AUTOSAR XML (schema 4-0-3)
package /ComponentTypes
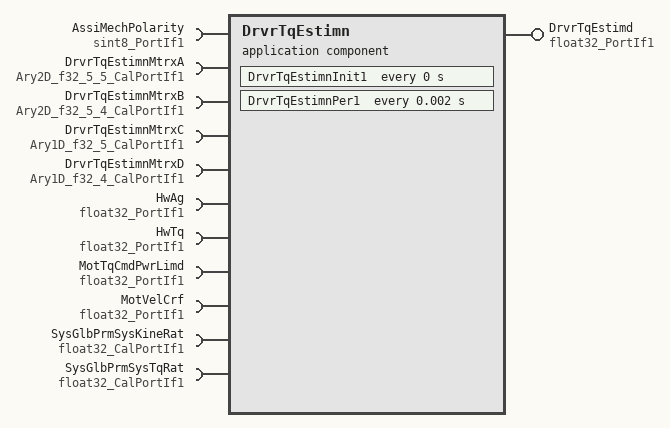
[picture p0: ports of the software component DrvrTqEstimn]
  application sw component type DrvrTqEstimn
    provide port DrvrTqEstimd: nonqueued-sender-com-spec{data-element=Val, init-value=0}, provided-interface=float32_PortIf1
    11 x require port:
      AssiMechPolarity: nonqueued-receiver-com-spec{data-element=Val, filter=data-filter-type=ALWAYS, init-value=1}, required-interface=sint8_PortIf1
      DrvrTqEstimnMtrxA: parameter-require-com-spec{init-value=[[-0.17159, 0.00010352, 1.1696, 0.00024516, 0.000019834], [-240.58, 0.060289, 240.53, 0.17028, 0.047148], [0.0018246, -0.0000042826, 0.99616, 0.00025897, -0.00000028965], [-6.1943, 0.014635, 5.9127, 0.11656, 0.00098854], [-70.875, -0.28572, 70.86, 0.053221, 0.98679]], parameter=Ary2D}, required-interface=Ary2D_f32_5_5_CalPortIf1
      DrvrTqEstimnMtrxB: parameter-require-com-spec{init-value=[[0.00000032994, 0.0081464, 0.0019034, 0.0016485], [0.00045434, 1.6329, 0.0015119, 0.76734], [0.0000011488, -0.000024566, 0.0019002, 0.001743], [0.0027499, 0.045004, 0.00025007, 0.86756], [0.0001448, 0.50816, -0.000025948, 0.23299]], parameter=Ary2D}, required-interface=Ary2D_f32_5_4_CalPortIf1
      DrvrTqEstimnMtrxC: parameter-require-com-spec{init-value=[0, 0, 0, 0, 1], parameter=Ary1D}, required-interface=Ary1D_f32_5_CalPortIf1
      DrvrTqEstimnMtrxD: parameter-require-com-spec{init-value=[0, 0, 0, 0], parameter=Ary1D}, required-interface=Ary1D_f32_4_CalPortIf1
      HwAg: nonqueued-receiver-com-spec{data-element=Val, filter=data-filter-type=ALWAYS, init-value=0}, required-interface=float32_PortIf1
      HwTq: nonqueued-receiver-com-spec{data-element=Val, filter=data-filter-type=ALWAYS, init-value=0}, required-interface=float32_PortIf1
      MotTqCmdPwrLimd: nonqueued-receiver-com-spec{data-element=Val, filter=data-filter-type=ALWAYS, init-value=0}, required-interface=float32_PortIf1
      MotVelCrf: nonqueued-receiver-com-spec{data-element=Val, filter=data-filter-type=ALWAYS, init-value=0}, required-interface=float32_PortIf1
      SysGlbPrmSysKineRat: parameter-require-com-spec{init-value=22, parameter=Val}, required-interface=float32_CalPortIf1
      SysGlbPrmSysTqRat: parameter-require-com-spec{init-value=20, parameter=Val}, required-interface=float32_CalPortIf1
    behavior DrvrTqEstimn_InternalBehavior
      ar-typed-per-instance-memorys:
        data DrvrTqStPrev: sw-calibration-access=READ-ONLY, type=Ary1D_f32_5
      timing event DrvrTqEstimn_InitEvent: start-on-event=DrvrTqEstimnInit1, period=0
      timing event TMT_DrvrTqEstimnPer1: start-on-event=DrvrTqEstimnPer1, period=0.002
      runnable DrvrTqEstimnInit1
      runnable DrvrTqEstimnPer1
        data-receive-point-by-arguments:
          5 x access:
            REC_AssiMechPolarity_Val: accessed-variable=AssiMechPolarity.Val
            REC_HwAg_Val: accessed-variable=HwAg.Val
            REC_HwTq_Val: accessed-variable=HwTq.Val
            REC_MotTqCmdPwrLimd_Val: accessed-variable=MotTqCmdPwrLimd.Val
            REC_MotVelCrf_Val: accessed-variable=MotVelCrf.Val
        data-send-points:
          access SEND_DrvrTqEstimd_Val: accessed-variable=DrvrTqEstimd.Val
  swc implementation DrvrTqEstimn_Implementation: behavior=DrvrTqEstimn_InternalBehavior
    code-descriptors:
      code Default: artifact-descriptors=autosar-engineering-object={short-label=Default, category=SWSRC}
